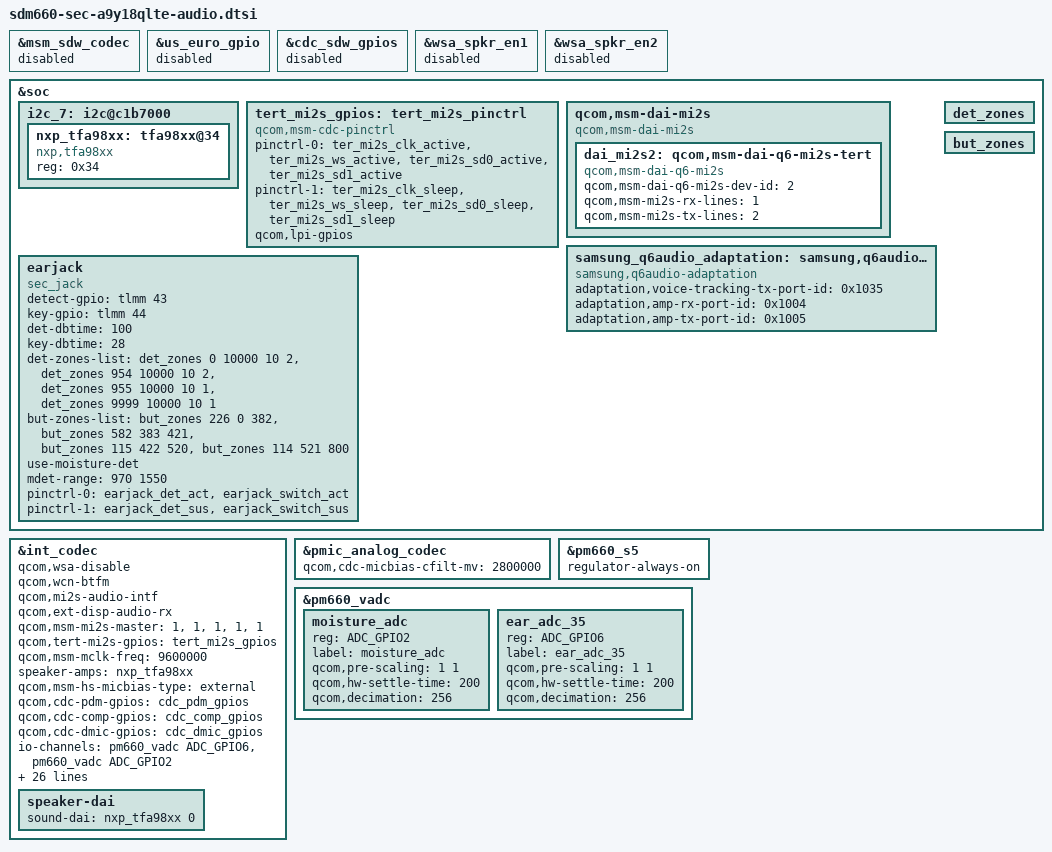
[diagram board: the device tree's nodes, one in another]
/* Copyright (c) 2016, The Linux Foundation. All rights reserved.
 *
 * This program is free software; you can redistribute it and/or modify
 * it under the terms of the GNU General Public License version 2 and
 * only version 2 as published by the Free Software Foundation.
 *
 * This program is distributed in the hope that it will be useful,
 * but WITHOUT ANY WARRANTY; without even the implied warranty of
 * MERCHANTABILITY or FITNESS FOR A PARTICULAR PURPOSE.  See the
 * GNU General Public License for more details.
 */

#include "../qcom/sdm660-internal-codec.dtsi"

&msm_sdw_codec {
	status = "disabled";
};

&us_euro_gpio {
	status = "disabled";
};

&cdc_sdw_gpios {
	status = "disabled";
};

&wsa_spkr_en1 {
	status = "disabled";
};

&wsa_spkr_en2 {
	status = "disabled";
};

&soc {
	i2c_7: i2c@c1b7000 { /* BLSP2 QUP3 */
		nxp_tfa98xx:tfa98xx@34{
			#sound-dai-cells = <1>;
			compatible = "nxp,tfa98xx";
			reg = <0x34>;
		};
	};
};

/*
 * 4.19: the card node is int_codec under qcom,msm-audio-apr/q6core-audio,
 * so override it instead of redefining soc/sound. Keep 4.19's asoc-cpu
 * lists (they name the 4.19 DAI devices, e.g. msm-dai-q6-dp.0, and add
 * QUIN MI2S); msm-mi2s-master needs one entry per MI2S_MAX (5) here.
 */
&int_codec {
	qcom,wsa-disable;
	qcom,wcn-btfm;
	qcom,mi2s-audio-intf;
	qcom,ext-disp-audio-rx;
	qcom,msm-mi2s-master = <1>, <1>, <1>, <1>, <1>;
	qcom,tert-mi2s-gpios = <&tert_mi2s_gpios>;
	qcom,msm-mclk-freq = <9600000>;
	speaker-amps = <&nxp_tfa98xx>;
	qcom,msm-hs-micbias-type = "external";
	qcom,cdc-pdm-gpios = <&cdc_pdm_gpios>;
	qcom,cdc-comp-gpios = <&cdc_comp_gpios>;
	qcom,cdc-dmic-gpios = <&cdc_dmic_gpios>;
	/* 4.19: IIO ADC5 channels replace qcom,{amux,moisture}-channel/-vadc */
	io-channels = <&pm660_vadc ADC_GPIO6>, <&pm660_vadc ADC_GPIO2>;
	io-channel-names = "earjack-read", "moisture-read";
	qcom,dmic-ldo-en = <&tlmm 24 0x0>;
	qcom,fm-lna-gpios = <&expander_gpios 20 0>;

	qcom,audio-routing =
		"RX_BIAS", "INT_MCLK0",
		"SPK_RX_BIAS", "INT_MCLK0",
		"INT_LDO_H", "INT_MCLK0",
		"RX_I2S_CLK", "INT_MCLK0",
		"TX_I2S_CLK", "INT_MCLK0",
		"AMIC2", "Headset Mic",
		"DMIC1", "Digital Mic1",
		"DMIC2", "Digital Mic1",
		"DMIC3", "Digital Mic3",
		"PDM_IN_RX1", "PDM_OUT_RX1",
		"PDM_IN_RX2", "PDM_OUT_RX2",
		"PDM_IN_RX3", "PDM_OUT_RX3",
		"ADC2_IN", "ADC2_OUT";

	asoc-platform = <&pcm0>, <&pcm1>, <&pcm2>, <&voip>, <&voice>,
			<&loopback>, <&compress>, <&hostless>,
			<&afe>, <&lsm>, <&routing>, <&compr>,
			 <&pcm_noirq>, <&samsung_q6audio_adaptation>;
	asoc-platform-names = "msm-pcm-dsp.0", "msm-pcm-dsp.1",
			"msm-pcm-dsp.2", "msm-voip-dsp",
			"msm-pcm-voice", "msm-pcm-loopback",
			"msm-compress-dsp", "msm-pcm-hostless",
			"msm-pcm-afe", "msm-lsm-client",
			"msm-pcm-routing", "msm-compr-dsp",
			"msm-pcm-dsp-noirq", "q6audio-adaptation";
	asoc-codec = <&stub_codec>, <&msm_digital_codec>,
			<&pmic_analog_codec>, <&ext_disp_audio_codec>;
	asoc-codec-names = "msm-stub-codec.1", "msm-dig-codec",
				"analog-codec",
				"msm-ext-disp-audio-codec-rx";

	/delete-property/qcom,auxpcm-audio-intf;
	/delete-property/qcom,msm-mbhc-hphl-swh;
	/delete-property/qcom,msm-mbhc-gnd-swh;
	/delete-property/qcom,us-euro-gpios;
	/delete-property/qcom,wsa-max-devs;
	/delete-property/qcom,wsa-devs;
	/delete-property/qcom,wsa-aux-dev-prefix;
	/delete-property/qcom,msm-micbias2-ext-cap;

	speaker-dai {
		sound-dai = <&nxp_tfa98xx 0>;
	};
};

&soc {
	tert_mi2s_gpios: tert_mi2s_pinctrl {
		compatible = "qcom,msm-cdc-pinctrl";
		pinctrl-names = "aud_active", "aud_sleep";
		pinctrl-0 = <&ter_mi2s_clk_active &ter_mi2s_ws_active
				&ter_mi2s_sd0_active &ter_mi2s_sd1_active>;
		pinctrl-1 = <&ter_mi2s_clk_sleep &ter_mi2s_ws_sleep
				&ter_mi2s_sd0_sleep &ter_mi2s_sd1_sleep>;
		qcom,lpi-gpios;
	};

	qcom,msm-dai-mi2s {
		compatible = "qcom,msm-dai-mi2s";
		dai_mi2s2: qcom,msm-dai-q6-mi2s-tert {
			compatible = "qcom,msm-dai-q6-mi2s";
			qcom,msm-dai-q6-mi2s-dev-id = <2>;
			qcom,msm-mi2s-rx-lines = <1>;
			qcom,msm-mi2s-tx-lines = <2>;
		};
	};

	samsung_q6audio_adaptation: samsung,q6audio-adaptation {
		compatible = "samsung,q6audio-adaptation";
		adaptation,voice-tracking-tx-port-id = <0x1035>;
		adaptation,amp-rx-port-id = <0x1004>;
		adaptation,amp-tx-port-id = <0x1005>;
	};

	det_zones: det_zones {
		#list-det-cells = <4>;
	};

	but_zones: but_zones {
		#list-but-cells = <3>;
	};

	earjack {
		compatible = "sec_jack";
		detect-gpio = <&tlmm 43 0x0>;
		key-gpio = <&tlmm 44 0x0>;
		det-dbtime = <100>;
		key-dbtime = <28>;

		det-zones-list = <&det_zones 0 10000 10 2>,
				 <&det_zones 954 10000 10 2>,
				 <&det_zones 955 10000 10 1>,
				 <&det_zones 9999 10000 10 1>;
		but-zones-list = <&but_zones 226 0 382>, /* KEY_MEDIA:226 */
				 <&but_zones 582 383 421>, /* KEY_VOICECOMMAND:582 */
				 <&but_zones 115 422 520>, /* KEY_VOLUMEUP:115 */
				 <&but_zones 114 521 800>; /* KEY_VOLUMEDOWN:114 */
				 
		use-moisture-det;
		mdet-range = <970 1550>;

		pinctrl-names = "earjack_gpio_active",
				"earjack_gpio_suspend";
		pinctrl-0 = <&earjack_det_act &earjack_switch_act>;
		pinctrl-1 = <&earjack_det_sus &earjack_switch_sus>;
	};

	/*
	 * 4.19: the DSPG DBMD4 voice wakeup chip (spi_8 + dbmdx nodes) is
	 * not ported; the ROM uses QTI's sound trigger instead.
	 */
};

&pmic_analog_codec {
	qcom,cdc-micbias-cfilt-mv = <2800000>;
};

&pm660_s5 {
	regulator-always-on;
};

/*
 * 4.19: the qpnp-vadc chan@13/chan@17 nodes in IIO ADC5 form: absolute
 * (no qcom,ratiometric), 1:1, 200 us settle, decimation 256 (4.4 index 0).
 */
&pm660_vadc {
	moisture_adc {
		reg = <ADC_GPIO2>;
		label = "moisture_adc";
		qcom,pre-scaling = <1 1>;
		qcom,hw-settle-time = <200>;
		qcom,decimation = <256>;
	};

	ear_adc_35 {
		reg = <ADC_GPIO6>;
		label = "ear_adc_35";
		qcom,pre-scaling = <1 1>;
		qcom,hw-settle-time = <200>;
		qcom,decimation = <256>;
	};
};

/*
 * The legacy qpnp-pin PM660 GPIO 3/9/11 setup lives in
 * sdm660-sec-a9y18qlte-pmic-gpio.dtsi; GPIO 2 (output, no consumer) is
 * left at its reset state.
 */
